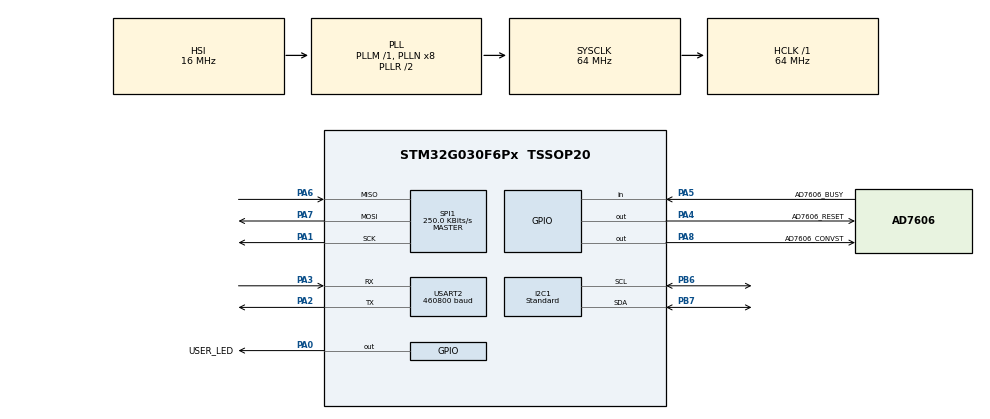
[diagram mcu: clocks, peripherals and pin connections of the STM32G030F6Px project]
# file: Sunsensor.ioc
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Dma.Request0=USART2_RX
Dma.Request1=USART2_TX
Dma.USART2_RX.0.Direction=DMA_PERIPH_TO_MEMORY
Dma.USART2_RX.0.EventEnable=DISABLE
Dma.USART2_RX.0.Instance=DMA1_Channel1
Dma.USART2_RX.0.MemDataAlignment=DMA_MDATAALIGN_BYTE
Dma.USART2_RX.0.MemInc=DMA_MINC_ENABLE
Dma.USART2_RX.0.Mode=DMA_CIRCULAR
Dma.USART2_RX.0.PeriphDataAlignment=DMA_PDATAALIGN_BYTE
Dma.USART2_RX.0.PeriphInc=DMA_PINC_DISABLE
Dma.USART2_RX.0.Polarity=HAL_DMAMUX_REQ_GEN_RISING
Dma.USART2_RX.0.Priority=DMA_PRIORITY_LOW
Dma.USART2_RX.0.RequestNumber=1
Dma.USART2_RX.0.SignalID=NONE
Dma.USART2_RX.0.SyncEnable=DISABLE
Dma.USART2_RX.0.SyncPolarity=HAL_DMAMUX_SYNC_NO_EVENT
Dma.USART2_RX.0.SyncRequestNumber=1
Dma.USART2_RX.0.SyncSignalID=NONE
Dma.USART2_TX.1.Direction=DMA_MEMORY_TO_PERIPH
Dma.USART2_TX.1.EventEnable=DISABLE
Dma.USART2_TX.1.Instance=DMA1_Channel2
Dma.USART2_TX.1.MemDataAlignment=DMA_MDATAALIGN_BYTE
Dma.USART2_TX.1.MemInc=DMA_MINC_ENABLE
Dma.USART2_TX.1.Mode=DMA_NORMAL
Dma.USART2_TX.1.PeriphDataAlignment=DMA_PDATAALIGN_BYTE
Dma.USART2_TX.1.PeriphInc=DMA_PINC_DISABLE
Dma.USART2_TX.1.Polarity=HAL_DMAMUX_REQ_GEN_RISING
Dma.USART2_TX.1.Priority=DMA_PRIORITY_LOW
Dma.USART2_TX.1.RequestNumber=1
Dma.USART2_TX.1.SignalID=NONE
Dma.USART2_TX.1.SyncEnable=DISABLE
Dma.USART2_TX.1.SyncPolarity=HAL_DMAMUX_SYNC_NO_EVENT
Dma.USART2_TX.1.SyncRequestNumber=1
Dma.USART2_TX.1.SyncSignalID=NONE
I2C1.I2C_Fall_Time=100
I2C1.I2C_Speed_Mode=I2C_Standard
I2C1.OwnAddress=PSD_ADDRESS
I2C1.Timing=0x10B17DB5
Mcu.Family=STM32G0
Mcu.Name=STM32G030F6Px
Mcu.Package=TSSOP20
NVIC.DMA1_Channel1_IRQn=true\:0\:0\:false\:false\:true\:false\:true\:true
NVIC.DMA1_Channel2_3_IRQn=true\:0\:0\:false\:false\:true\:false\:true\:true
NVIC.I2C1_IRQn=true\:0\:0\:false\:false\:true\:true\:true\:true
NVIC.USART2_IRQn=true\:0\:0\:false\:false\:true\:true\:true\:true
PA0.GPIO_Label=USER_LED
PA0.PinState=GPIO_PIN_SET
PA0.Signal=GPIO_Output
PA1.Mode=Full_Duplex_Master
PA1.Signal=SPI1_SCK
PA13.Mode=Serial_Wire
PA13.Signal=SYS_SWDIO
PA14-BOOT0.Mode=Serial_Wire
PA14-BOOT0.Signal=SYS_SWCLK
PA14-BOOT0__PA15.StandardMode=true
PA2.Mode=Asynchronous
PA2.Signal=USART2_TX
PA3.Mode=Asynchronous
PA3.Signal=USART2_RX
PA4.GPIO_Label=AD7606_RESET
PA4.Signal=GPIO_Output
PA5.GPIO_Label=AD7606_BUSY
PA5.Signal=GPIO_Input
PA6.Mode=Full_Duplex_Master
PA6.Signal=SPI1_MISO
PA7.Mode=Full_Duplex_Master
PA7.Signal=SPI1_MOSI
PA8.GPIO_Label=AD7606_CONVST
PA8.Signal=GPIO_Output
PB0__PB1__PB2__PA8.StandardMode=true
PB3__PB4__PB5__PB6.StandardMode=true
PB6.Mode=I2C
PB6.Signal=I2C1_SCL
PB7.Mode=I2C
PB7.Signal=I2C1_SDA
PB7__PB8.StandardMode=true
PC14-OSC32_IN\ (PC14)__PB9.StandardMode=true
ProjectManager.HeapSize=0x200
ProjectManager.StackSize=0x400
ProjectManager.TargetToolchain=MDK-ARM V5.32
RCC.ADCFreq_Value=64000000
RCC.AHBFreq_Value=64000000
RCC.CortexFreq_Value=64000000
RCC.EXTERNAL_CLOCK_VALUE=12288000
RCC.HCLKFreq_Value=64000000
RCC.HSE_VALUE=8000000
RCC.HSI_VALUE=16000000
RCC.LSE_VALUE=32768
RCC.SYSCLKFreq_VALUE=64000000
RCC.SYSCLKSource=RCC_SYSCLKSOURCE_PLLCLK
RCC.VCOOutputFreq_Value=128000000
SPI1.BaudRatePrescaler=SPI_BAUDRATEPRESCALER_256
SPI1.CLKPhase=SPI_PHASE_2EDGE
SPI1.CLKPolarity=SPI_POLARITY_HIGH
SPI1.CRCCalculation=SPI_CRCCALCULATION_DISABLE
SPI1.CalculateBaudRate=250.0 KBits/s
SPI1.DataSize=SPI_DATASIZE_8BIT
SPI1.Direction=SPI_DIRECTION_2LINES
SPI1.Mode=SPI_MODE_MASTER
SPI1.VirtualType=VM_MASTER
USART2.BaudRate=460800
USART2.VirtualMode-Asynchronous=VM_ASYNC
board=custom

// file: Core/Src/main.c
/* USER CODE BEGIN Header */
/**
  ******************************************************************************
  * @file           : main.c
  * @brief          : Main program body
  ******************************************************************************
  * @attention
  *
  * Copyright (c) 2025 STMicroelectronics.
  * All rights reserved.
  *
  * This software is licensed under terms that can be found in the LICENSE file
  * in the root directory of this software component.
  * If no LICENSE file comes with this software, it is provided AS-IS.
  *
  ******************************************************************************
  */
/* USER CODE END Header */
#include "main.h"
#include "dma.h"
#include "i2c.h"
#include "spi.h"
#include "usart.h"
#include "gpio.h"

void SystemClock_Config(void);

int main(void)
{

  /* MCU Configuration--------------------------------------------------------*/

  /* Reset of all peripherals, Initializes the Flash interface and the Systick. */
  HAL_Init();

  /* Configure the system clock */
  SystemClock_Config();

  /* Initialize all configured peripherals */
  MX_GPIO_Init();
  MX_DMA_Init();
  MX_I2C1_Init();
  MX_SPI1_Init();
  MX_USART2_UART_Init();
  /* USER CODE BEGIN 2 */
    bsp_Init();
    printf("Hello\r\n");

    Demo_spi_AD7606();

  /* USER CODE END 2 */

  /* Infinite loop */
    while (1)
    {

    }
}

void SystemClock_Config(void)
{
  RCC_OscInitTypeDef RCC_OscInitStruct = {0};
  RCC_ClkInitTypeDef RCC_ClkInitStruct = {0};

  /** Configure the main internal regulator output voltage
  */
  HAL_PWREx_ControlVoltageScaling(PWR_REGULATOR_VOLTAGE_SCALE1);

  /** Initializes the RCC Oscillators according to the specified parameters
  * in the RCC_OscInitTypeDef structure.
  */
  RCC_OscInitStruct.OscillatorType = RCC_OSCILLATORTYPE_HSI;
  RCC_OscInitStruct.HSIState = RCC_HSI_ON;
  RCC_OscInitStruct.HSIDiv = RCC_HSI_DIV1;
  RCC_OscInitStruct.HSICalibrationValue = RCC_HSICALIBRATION_DEFAULT;
  RCC_OscInitStruct.PLL.PLLState = RCC_PLL_ON;
  RCC_OscInitStruct.PLL.PLLSource = RCC_PLLSOURCE_HSI;
  RCC_OscInitStruct.PLL.PLLM = RCC_PLLM_DIV1;
  RCC_OscInitStruct.PLL.PLLN = 8;
  RCC_OscInitStruct.PLL.PLLP = RCC_PLLP_DIV2;
  RCC_OscInitStruct.PLL.PLLR = RCC_PLLR_DIV2;
  if (HAL_RCC_OscConfig(&RCC_OscInitStruct) != HAL_OK)
  {
    Error_Handler();
  }

  /** Initializes the CPU, AHB and APB buses clocks
  */
  RCC_ClkInitStruct.ClockType = RCC_CLOCKTYPE_HCLK|RCC_CLOCKTYPE_SYSCLK
                              |RCC_CLOCKTYPE_PCLK1;
  RCC_ClkInitStruct.SYSCLKSource = RCC_SYSCLKSOURCE_PLLCLK;
  RCC_ClkInitStruct.AHBCLKDivider = RCC_SYSCLK_DIV1;
  RCC_ClkInitStruct.APB1CLKDivider = RCC_HCLK_DIV1;

  if (HAL_RCC_ClockConfig(&RCC_ClkInitStruct, FLASH_LATENCY_2) != HAL_OK)
  {
    Error_Handler();
  }
}

void Error_Handler(void)
{
  /* USER CODE BEGIN Error_Handler_Debug */
    /* User can add his own implementation to report the HAL error return state */
    //  __disable_irq();
    while (1)
    {
        LED_TOGGLE();
        HAL_Delay(100);
    }

  /* USER CODE END Error_Handler_Debug */
}
